# MKE04Z1284 register map
Vendor: Freescale Semiconductor, Inc.; File version: 1.6
CPU: CM0PLUS r0p0, little endian, no MPU, no FPU, 0x2 interrupt priority bits, 0x0 interrupts
Registers are 32-bit, read-write, reset 0x0 unless marked. A register's access mark holds for its fields unless they carry their own. Offsets are from the block's base; [hi:lo] are bit positions.

## RTC — Real-time counter
Base 0x4003D000; register names take the prefix RTC_
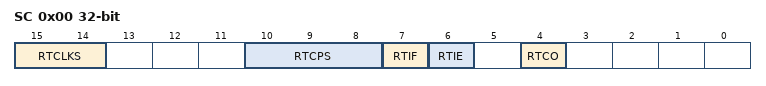
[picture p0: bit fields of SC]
0x00 SC — RTC Status and Control Register
  [15:14] RTCLKS — Real-Time Clock Source Select
    0=External clock source; 1=Real-time clock source is 1 kHz (LPOCLK); 2=Internal reference clock (ICSIRCLK); 3=Bus clock
  [10:8] RTCPS — Real-Time Clock Prescaler Select
    0=Off; 1=If RTCLKS = x0, it is 1; if RTCLKS = x1, it is 128; 2=If RTCLKS = x0, it is 2; if RTCLKS = x1, it is 256; 3=If RTCLKS = x0, it is 4; if RTCLKS = x1, it is 512; 4=If RTCLKS = x0, it is 8; if RTCLKS = x1, it is 1024; 5=If RTCLKS = x0, it is 16; if RTCLKS = x1, it is 2048; 6=If RTCLKS = x0, it is 32; if RTCLKS = x1, it is 100; 7=If RTCLKS = x0, it is 64; if RTCLKS = x1, it is 1000
  [7] RTIF — Real-Time Interrupt Flag
    0=RTC counter has not reached the value in the RTC modulo register; 1=RTC counter has reached the value in the RTC modulo register
  [6] RTIE — Real-Time Interrupt Enable
    0=Real-time interrupt requests are disabled. Use software polling.; 1=Real-time interrupt requests are enabled
  [4] RTCO — Real-Time Counter Output
    0=Real-time counter output disabled; 1=Real-time counter output enabled
0x04 MOD — RTC Modulo Register
  [15:0] MOD — RTC Modulo
0x08 CNT ro — RTC Counter Register
  [15:0] CNT — RTC Count

## WDOG — Watchdog timer
Base 0x40052000; register names take the prefix WDOG_
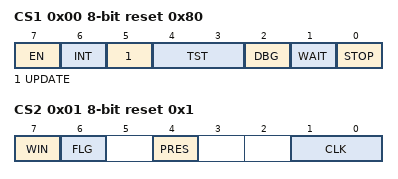
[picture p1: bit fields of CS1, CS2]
0x00 CS1 8-bit reset 0x80 — Watchdog Control and Status Register 1
  [7] EN — Watchdog Enable
    0=Watchdog disabled; 1=Watchdog enabled
  [6] INT — Watchdog Interrupt
    0=Watchdog interrupts are disabled. Watchdog resets are not delayed.; 1=Watchdog interrupts are enabled. Watchdog resets are delayed by 128 bus clocks.
  [5] UPDATE — Allow updates
    0=Updates not allowed. After the initial configuration, the watchdog cannot be later modified without forcing a reset.; 1=Updates allowed. Software can modify the watchdog configuration registers within 128 bus clocks after performing the unlock write sequence.
  [4:3] TST — Watchdog Test
    0=Watchdog test mode disabled; 1=Watchdog user mode enabled. (Watchdog test mode disabled.) After testing the watchdog, software should use this setting to indicate that the watchdog is functioning normally in user mode.; 2=Watchdog test mode enabled, only the low byte is used. WDOG_CNTL is compared with WDOG_TOVALL.; 3=Watchdog test mode enabled, only the high byte is used. WDOG_CNTH is compared with WDOG_TOVALH.
  [2] DBG — Debug Enable
    0=Watchdog disabled in chip debug mode; 1=Watchdog enabled in chip debug mode
  [1] WAIT — Wait Enable
    0=Watchdog disabled in chip wait mode; 1=Watchdog enabled in chip wait mode
  [0] STOP — Stop Enable
    0=Watchdog disabled in chip stop mode; 1=Watchdog enabled in chip stop mode
0x01 CS2 8-bit reset 0x1 — Watchdog Control and Status Register 2
  [7] WIN — Watchdog Window
    0=Window mode disabled; 1=Window mode enabled
  [6] FLG — Watchdog Interrupt Flag
    0=No interrupt occurred; 1=An interrupt occurred
  [4] PRES — Watchdog Prescalar
    0=256 prescalar disabled; 1=256 prescalar enabled
  [1:0] CLK — Watchdog Clock
    0=Bus clock; 1=1 kHz internal low-power oscillator (LPOCLK); 2=32 kHz internal oscillator (ICSIRCLK); 3=External clock source
0x02 CNT 16-bit (WDOG view) — Watchdog Counter Register.
  [15:0] CNT — Watchdog Counter Value
0x02 CNTH 8-bit ro (WDOG view) — Watchdog Counter Register: High
  [7:0] CNTHIGH — High byte of the Watchdog Counter
0x03 CNTL 8-bit ro — Watchdog Counter Register: Low
  [7:0] CNTLOW — Low byte of the Watchdog Counter
0x04 TOVAL 16-bit (WDOG view) — Watchdog Timeout Value Register.
  [15:0] TOVAL — Watchdog Timeout Value
0x04 TOVALH 8-bit (WDOG view) — Watchdog Timeout Value Register: High
  [7:0] TOVALHIGH — High byte of the timeout value
0x05 TOVALL 8-bit reset 0x4 — Watchdog Timeout Value Register: Low
  [7:0] TOVALLOW — Low byte of the timeout value
0x06 WIN 16-bit (WDOG view) — Watchdog Window Register.
  [15:0] WIN — Watchdog Window Value
0x06 WINH 8-bit (WDOG view) — Watchdog Window Register: High
  [7:0] WINHIGH — High byte of Watchdog Window
0x07 WINL 8-bit — Watchdog Window Register: Low
  [7:0] WINLOW — Low byte of Watchdog Window
